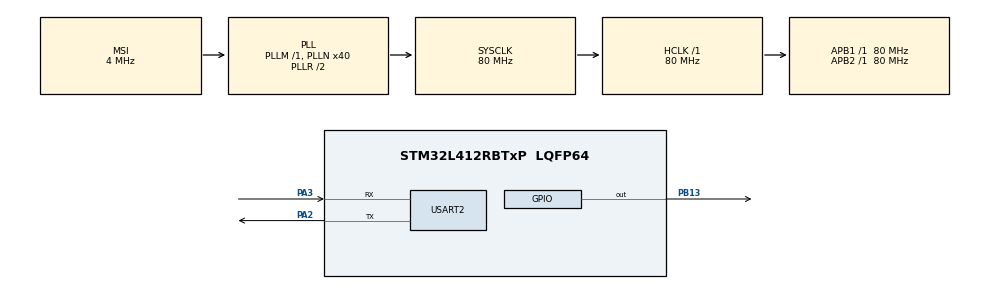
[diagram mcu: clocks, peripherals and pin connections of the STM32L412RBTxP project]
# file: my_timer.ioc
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FREERTOS.Tasks01=defaultTask,0,128,StartDefaultTask,Default,NULL,Dynamic,NULL,NULL
Mcu.Family=STM32L4
Mcu.Name=STM32L412RBTxP
Mcu.Package=LQFP64
NVIC.PriorityGroup=NVIC_PRIORITYGROUP_4
NVIC.TIM2_IRQn=true\:0\:0\:false\:false\:true\:false\:false\:true
NVIC.TIM6_IRQn=true\:5\:0\:false\:false\:true\:true\:true\:true
NVIC.TimeBase=TIM2_IRQn
NVIC.TimeBaseIP=TIM2
PA2.Mode=Asynchronous
PA2.Signal=USART2_TX
PA3.Mode=Asynchronous
PA3.Signal=USART2_RX
PB13.Signal=GPIO_Output
ProjectManager.HeapSize=0x200
ProjectManager.StackSize=0x400
ProjectManager.TargetToolchain=STM32CubeIDE
RCC.ADCFreq_Value=80000000
RCC.AHBFreq_Value=80000000
RCC.APB1Freq_Value=80000000
RCC.APB1TimFreq_Value=80000000
RCC.APB2Freq_Value=80000000
RCC.APB2TimFreq_Value=80000000
RCC.CortexFreq_Value=80000000
RCC.HCLKFreq_Value=80000000
RCC.HSE_VALUE=8000000
RCC.HSI48_VALUE=48000000
RCC.HSI_VALUE=16000000
RCC.LSE_VALUE=32768
RCC.MSI_VALUE=4000000
RCC.PLLN=40
RCC.SYSCLKFreq_VALUE=80000000
RCC.SYSCLKSource=RCC_SYSCLKSOURCE_PLLCLK
RCC.USBFreq_Value=4000000
RCC.VCOOutputFreq_Value=160000000
TIM6.Period=800-1
TIM6.Prescaler=100-1
USART2.VirtualMode-Asynchronous=VM_ASYNC
VP_FREERTOS_VS_CMSIS_V1.Mode=CMSIS_V1
VP_SYS_VS_tim2.Mode=TIM2
VP_TIM6_VS_ClockSourceINT.Mode=Enable_Timer
board=custom

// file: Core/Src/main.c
/* USER CODE BEGIN Header */
/**
  ******************************************************************************
  * @file           : main.c
  * @brief          : Main program body
  ******************************************************************************
  * @attention
  *
  * <h2><center>&copy; Copyright (c) 2021 STMicroelectronics.
  * All rights reserved.</center></h2>
  *
  * This software component is licensed by ST under BSD 3-Clause license,
  * the "License"; You may not use this file except in compliance with the
  * License. You may obtain a copy of the License at:
  *                        opensource.org/licenses/BSD-3-Clause
  *
  ******************************************************************************
  */
/* USER CODE END Header */
#include "main.h"
#include "cmsis_os.h"
#include "tim.h"
#include "usart.h"
#include "gpio.h"

/* USER CODE BEGIN Includes */
#include <stdio.h>
//#include "freertos.h"
/* USER CODE END Includes */

/* USER CODE BEGIN PTD */
uint8_t queTrue = 1;
/* USER CODE END PTD */

/* USER CODE BEGIN PD */
#ifdef __GNUC__
    #define PUTCHAR_PROTOTYPE int __io_putchar(int ch)
#else
    #define PUTCHAR_PROTOTYPE int fputc(int ch, FILE *f)
#endif

PUTCHAR_PROTOTYPE
{
  HAL_UART_Transmit(&huart2, (uint8_t *)&ch, 1, 0xFFFF);
  return ch;
}
/* USER CODE END PD */

void SystemClock_Config(void);
void MX_FREERTOS_Init(void);

int main(void)
{

  /* MCU Configuration--------------------------------------------------------*/

  /* Reset of all peripherals, Initializes the Flash interface and the Systick. */
  HAL_Init();

  /* Configure the system clock */
  SystemClock_Config();

  /* Initialize all configured peripherals */
  MX_GPIO_Init();
  MX_USART2_UART_Init();
  MX_TIM6_Init();
  /* USER CODE BEGIN 2 */
  HAL_TIM_Base_Start_IT(&htim6);

  /* USER CODE END 2 */

  /* Call init function for freertos objects (in freertos.c) */
  MX_FREERTOS_Init();
  /* Start scheduler */
  osKernelStart();

  /* We should never get here as control is now taken by the scheduler */
  /* Infinite loop */
  /* USER CODE BEGIN WHILE */

  while (1)
  {
#if 0
    if (my_arr <3)
    {
//      my_arr = 1;
      HAL_GPIO_WritePin(GPIOB, GPIO_PIN_13, GPIO_PIN_SET);
      if (ignore_arr == 10000)
      {
        ignore_arr = 1;
      }
    }
    else
    {
      if (my_arr > 10)
      {
        my_arr = 1;
      }
      HAL_GPIO_WritePin(GPIOB, GPIO_PIN_13, GPIO_PIN_RESET);
    }
#else

#endif

    /* USER CODE END WHILE */

  }
}

void SystemClock_Config(void)
{
  RCC_OscInitTypeDef RCC_OscInitStruct = {0};
  RCC_ClkInitTypeDef RCC_ClkInitStruct = {0};
  RCC_PeriphCLKInitTypeDef PeriphClkInit = {0};

  /** Configure the main internal regulator output voltage
  */
  if (HAL_PWREx_ControlVoltageScaling(PWR_REGULATOR_VOLTAGE_SCALE1) != HAL_OK)
  {
    Error_Handler();
  }
  /** Initializes the RCC Oscillators according to the specified parameters
  * in the RCC_OscInitTypeDef structure.
  */
  RCC_OscInitStruct.OscillatorType = RCC_OSCILLATORTYPE_MSI;
  RCC_OscInitStruct.MSIState = RCC_MSI_ON;
  RCC_OscInitStruct.MSICalibrationValue = 0;
  RCC_OscInitStruct.MSIClockRange = RCC_MSIRANGE_6;
  RCC_OscInitStruct.PLL.PLLState = RCC_PLL_ON;
  RCC_OscInitStruct.PLL.PLLSource = RCC_PLLSOURCE_MSI;
  RCC_OscInitStruct.PLL.PLLM = 1;
  RCC_OscInitStruct.PLL.PLLN = 40;
  RCC_OscInitStruct.PLL.PLLQ = RCC_PLLQ_DIV2;
  RCC_OscInitStruct.PLL.PLLR = RCC_PLLR_DIV2;
  if (HAL_RCC_OscConfig(&RCC_OscInitStruct) != HAL_OK)
  {
    Error_Handler();
  }
  /** Initializes the CPU, AHB and APB buses clocks
  */
  RCC_ClkInitStruct.ClockType = RCC_CLOCKTYPE_HCLK|RCC_CLOCKTYPE_SYSCLK
                              |RCC_CLOCKTYPE_PCLK1|RCC_CLOCKTYPE_PCLK2;
  RCC_ClkInitStruct.SYSCLKSource = RCC_SYSCLKSOURCE_PLLCLK;
  RCC_ClkInitStruct.AHBCLKDivider = RCC_SYSCLK_DIV1;
  RCC_ClkInitStruct.APB1CLKDivider = RCC_HCLK_DIV1;
  RCC_ClkInitStruct.APB2CLKDivider = RCC_HCLK_DIV1;

  if (HAL_RCC_ClockConfig(&RCC_ClkInitStruct, FLASH_LATENCY_4) != HAL_OK)
  {
    Error_Handler();
  }
  PeriphClkInit.PeriphClockSelection = RCC_PERIPHCLK_USART2;
  PeriphClkInit.Usart2ClockSelection = RCC_USART2CLKSOURCE_PCLK1;
  if (HAL_RCCEx_PeriphCLKConfig(&PeriphClkInit) != HAL_OK)
  {
    Error_Handler();
  }
}

 /**
  * @brief  Period elapsed callback in non blocking mode
  * @note   This function is called  when TIM2 interrupt took place, inside
  * HAL_TIM_IRQHandler(). It makes a direct call to HAL_IncTick() to increment
  * a global variable "uwTick" used as application time base.
  * @param  htim : TIM handle
  * @retval None
  */
void HAL_TIM_PeriodElapsedCallback(TIM_HandleTypeDef *htim)
{
  if (htim->Instance == TIM2) {
    HAL_IncTick();
  }
}

void Error_Handler(void)
{
  __disable_irq();
  while (1)
  {
  }
}

/************************ (C) COPYRIGHT STMicroelectronics *****END OF FILE****/

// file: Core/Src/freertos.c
/* USER CODE BEGIN Header */
/**
  ******************************************************************************
  * File Name          : freertos.c
  * Description        : Code for freertos applications
  ******************************************************************************
  * @attention
  *
  * <h2><center>&copy; Copyright (c) 2021 STMicroelectronics.
  * All rights reserved.</center></h2>
  *
  * This software component is licensed by ST under Ultimate Liberty license
  * SLA0044, the "License"; You may not use this file except in compliance with
  * the License. You may obtain a copy of the License at:
  *                             www.st.com/SLA0044
  *
  ******************************************************************************
  */
/* USER CODE END Header */

#include "FreeRTOS.h"
#include "task.h"
#include "main.h"
#include "cmsis_os.h"

/* USER CODE BEGIN Includes */
#include <stdio.h>

/* USER CODE END Includes */

/* USER CODE BEGIN Variables */

uint8_t my_arr = 1;
uint16_t ignore_arr = 1;

TaskHandle_t myTaskHandle = NULL;
QueueHandle_t myQueueHandle = NULL;

/* USER CODE END Variables */
osThreadId defaultTaskHandle;

/* USER CODE BEGIN FunctionPrototypes */
void myQueueSendFromISR(uint8_t* queMSG);
void my_Task();

/* USER CODE END FunctionPrototypes */

void StartDefaultTask(void const * argument);

void MX_FREERTOS_Init(void); /* (MISRA C 2004 rule 8.1) */

/* GetIdleTaskMemory prototype (linked to static allocation support) */
void vApplicationGetIdleTaskMemory( StaticTask_t **ppxIdleTaskTCBBuffer, StackType_t **ppxIdleTaskStackBuffer, uint32_t *pulIdleTaskStackSize );

/* USER CODE BEGIN GET_IDLE_TASK_MEMORY */
static StaticTask_t xIdleTaskTCBBuffer;
static StackType_t xIdleStack[configMINIMAL_STACK_SIZE];

void vApplicationGetIdleTaskMemory( StaticTask_t **ppxIdleTaskTCBBuffer, StackType_t **ppxIdleTaskStackBuffer, uint32_t *pulIdleTaskStackSize )
{
  *ppxIdleTaskTCBBuffer = &xIdleTaskTCBBuffer;
  *ppxIdleTaskStackBuffer = &xIdleStack[0];
  *pulIdleTaskStackSize = configMINIMAL_STACK_SIZE;
  /* place for user code */
}
/* USER CODE END GET_IDLE_TASK_MEMORY */

void MX_FREERTOS_Init(void) {

  /* Create the thread(s) */
  /* definition and creation of defaultTask */
  osThreadDef(defaultTask, StartDefaultTask, osPriorityNormal, 0, 128);
  defaultTaskHandle = osThreadCreate(osThread(defaultTask), NULL);

  /* USER CODE BEGIN RTOS_THREADS */
  /* add threads, ... */

  myQueueHandle = xQueueCreate(4, sizeof(uint8_t));

  xTaskCreate(my_Task, "myTask", configMINIMAL_STACK_SIZE, NULL, 1, &myTaskHandle);

  /* USER CODE END RTOS_THREADS */

}

void StartDefaultTask(void const * argument)
{
  for(;;)
  {
    osDelay(1);
  }
}

/* USER CODE BEGIN Application */

void myQueueSendFromISR(uint8_t* queMSG)
{
  BaseType_t xHigherPriorityTaskWoken = pdFALSE;
  if (myQueueHandle != NULL)
  {
    xQueueSendFromISR(myQueueHandle, queMSG, &xHigherPriorityTaskWoken);
  }
}

void my_Task()
{
	uint8_t * quqMSG;
	for (;;)
	{
		if (xQueueReceive(myQueueHandle, &quqMSG, 1)==pdTRUE)
		{
			my_arr++;
			ignore_arr++;
		}
		if (my_arr<3)
		{
			HAL_GPIO_WritePin(GPIOB, GPIO_PIN_13, GPIO_PIN_SET);
		}
		else
		{
			HAL_GPIO_WritePin(GPIOB, GPIO_PIN_13, GPIO_PIN_RESET);
			if (my_arr==10)
			{
				my_arr = 1;
			}
		}

	}
}
/* USER CODE END Application */

/************************ (C) COPYRIGHT STMicroelectronics *****END OF FILE****/
